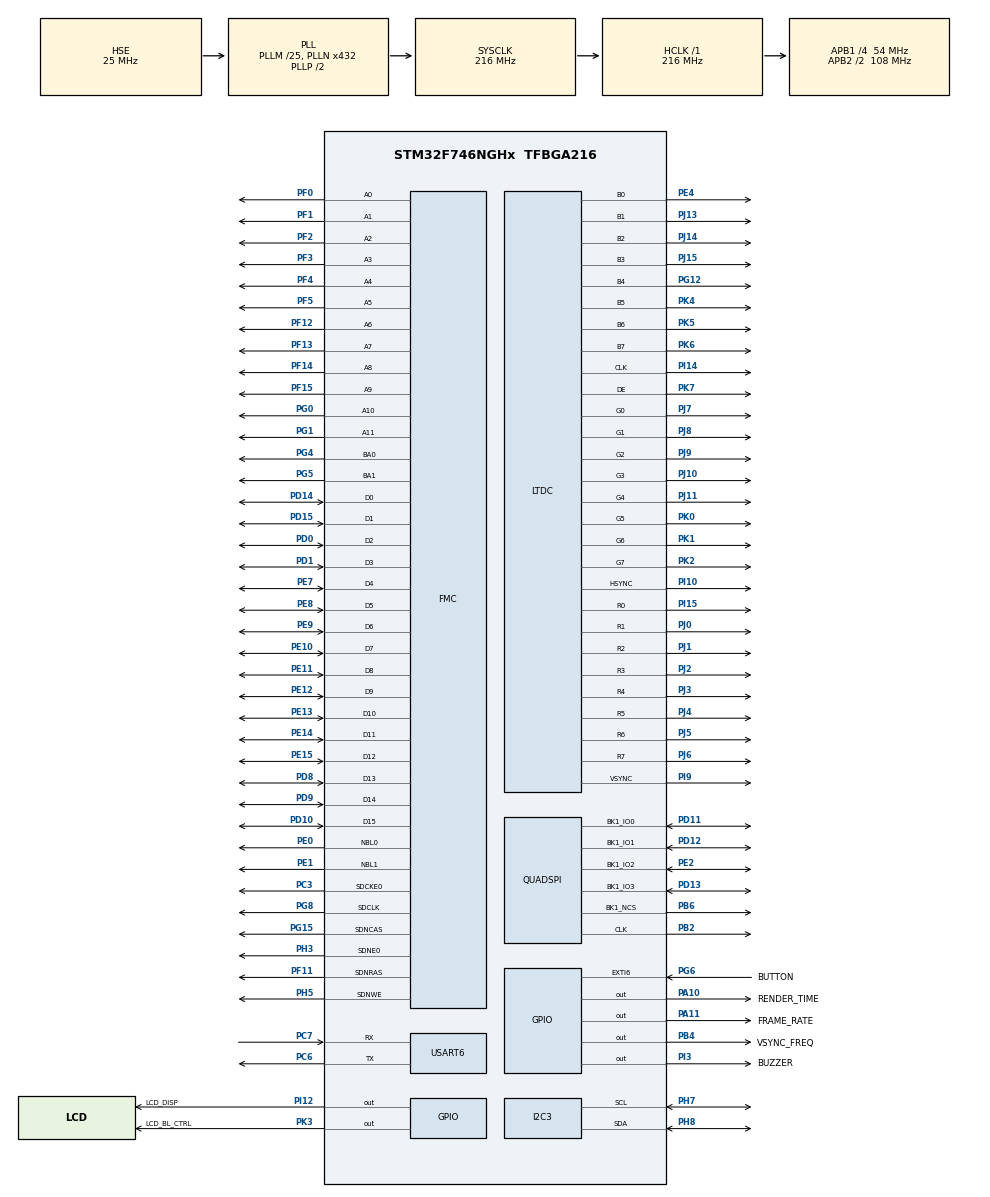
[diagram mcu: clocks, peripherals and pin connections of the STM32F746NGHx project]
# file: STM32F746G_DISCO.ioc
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CORTEX_M7.ART_ACCLERATOR_ENABLE=1
CORTEX_M7.AccessPermission-Cortex_Memory_Protection_Unit_Region0_Settings=MPU_REGION_FULL_ACCESS
CORTEX_M7.AccessPermission-Cortex_Memory_Protection_Unit_Region1_Settings=MPU_REGION_FULL_ACCESS
CORTEX_M7.BaseAddress-Cortex_Memory_Protection_Unit_Region0_Settings=0x90000000
CORTEX_M7.BaseAddress-Cortex_Memory_Protection_Unit_Region1_Settings=0x90000000
CORTEX_M7.CPU_DCache=Enabled
CORTEX_M7.CPU_ICache=Enabled
CORTEX_M7.Enable-Cortex_Memory_Protection_Unit_Region0_Settings=MPU_REGION_ENABLE
CORTEX_M7.Enable-Cortex_Memory_Protection_Unit_Region1_Settings=MPU_REGION_ENABLE
CORTEX_M7.IsCacheable-Cortex_Memory_Protection_Unit_Region1_Settings=MPU_ACCESS_CACHEABLE
CORTEX_M7.MPU_Control=MPU_PRIVILEGED_DEFAULT
CORTEX_M7.PREFETCH_ENABLE=1
CORTEX_M7.Size-Cortex_Memory_Protection_Unit_Region0_Settings=MPU_REGION_SIZE_256MB
CORTEX_M7.Size-Cortex_Memory_Protection_Unit_Region1_Settings=MPU_REGION_SIZE_16MB
FMC.CASLatency1=FMC_SDRAM_CAS_LATENCY_3
FMC.ExitSelfRefreshDelay1=7
FMC.LoadToActiveDelay1=2
FMC.RCDDelay1=2
FMC.RPDelay1=2
FMC.ReadBurst1=FMC_SDRAM_RBURST_ENABLE
FMC.RowCycleDelay1=7
FMC.SDClockPeriod1=FMC_SDRAM_CLOCK_PERIOD_2
FMC.SelfRefreshTime1=4
FMC.WriteRecoveryTime1=3
FREERTOS.Queues01=uartQueue,2,uint8_t,0,Dynamic,NULL,NULL
FREERTOS.Tasks01=defaultTask,24,128,StartDefaultTask,Default,NULL,Dynamic,NULL,NULL;TouchGFXTask,24,4096,TouchGFX_Task,As external,NULL,Dynamic,NULL,NULL;videoTask,8,1000,videoTaskFunc,As external,NULL,Dynamic,NULL,NULL
FREERTOS.configTOTAL_HEAP_SIZE=75000
FREERTOS.configUSE_APPLICATION_TASK_TAG=1
FREERTOS.configUSE_IDLE_HOOK=1
I2C3.Timing=0x20404768
LIBJPEG.RGB_ORDERING=BGR
LTDC.ActiveH=272
LTDC.ActiveW=480
LTDC.Alpha_L0=255
LTDC.FBStartAdress_L0=0xC0000000
LTDC.HBP=13
LTDC.HFP=32
LTDC.HSync=41
LTDC.ImageHeight_L0=272
LTDC.ImageWidth_L0=480
LTDC.Layers=0
LTDC.PixelFormat_L0=LTDC_PIXEL_FORMAT_RGB565
LTDC.VSync=10
LTDC.WindowX1_L0=480
LTDC.WindowY1_L0=272
Mcu.Family=STM32F7
Mcu.Name=STM32F746NGHx
Mcu.Package=TFBGA216
NVIC.DMA2D_IRQn=true\:5\:0\:true\:false\:true\:true\:true\:true\:true
NVIC.EXTI9_5_IRQn=true\:5\:0\:false\:false\:true\:true\:true\:true\:true
NVIC.LTDC_IRQn=true\:5\:0\:true\:false\:true\:true\:true\:true\:true
NVIC.PriorityGroup=NVIC_PRIORITYGROUP_4
NVIC.TIM6_DAC_IRQn=true\:0\:0\:false\:false\:true\:false\:false\:true\:true
NVIC.TimeBase=TIM6_DAC_IRQn
NVIC.TimeBaseIP=TIM6
NVIC.USART6_IRQn=true\:5\:0\:false\:false\:true\:true\:true\:true\:true
PA10.GPIO_Label=RENDER_TIME
PA10.GPIO_Speed=GPIO_SPEED_FREQ_VERY_HIGH
PA10.Signal=GPIO_Output
PA11.GPIO_Label=FRAME_RATE
PA11.GPIO_Speed=GPIO_SPEED_FREQ_VERY_HIGH
PA11.Signal=GPIO_Output
PA13.Mode=Serial_Wire
PA13.Signal=SYS_JTMS-SWDIO
PA14.Mode=Serial_Wire
PA14.Signal=SYS_JTCK-SWCLK
PB2.Mode=Single Bank 1
PB2.Signal=QUADSPI_CLK
PB4.GPIO_Label=VSYNC_FREQ
PB4.GPIO_Speed=GPIO_SPEED_FREQ_VERY_HIGH
PB4.Signal=GPIO_Output
PB6.Mode=Single Bank 1
PB6.Signal=QUADSPI_BK1_NCS
PC3.Mode=SdramChipSelect1_1
PC3.Signal=FMC_SDCKE0
PC6.Mode=Asynchronous
PC6.Signal=USART6_TX
PC7.Mode=Asynchronous
PC7.Signal=USART6_RX
PD0.Signal=FMC_D2_DA2
PD1.Signal=FMC_D3_DA3
PD10.Signal=FMC_D15_DA15
PD11.Mode=Single Bank 1
PD11.Signal=QUADSPI_BK1_IO0
PD12.Mode=Single Bank 1
PD12.Signal=QUADSPI_BK1_IO1
PD13.Mode=Single Bank 1
PD13.Signal=QUADSPI_BK1_IO3
PD14.Signal=FMC_D0_DA0
PD15.Signal=FMC_D1_DA1
PD8.Signal=FMC_D13_DA13
PD9.Signal=FMC_D14_DA14
PE0.Signal=FMC_NBL0
PE1.Signal=FMC_NBL1
PE10.Signal=FMC_D7_DA7
PE11.Signal=FMC_D8_DA8
PE12.Signal=FMC_D9_DA9
PE13.Signal=FMC_D10_DA10
PE14.Signal=FMC_D11_DA11
PE15.Signal=FMC_D12_DA12
PE2.Mode=Single Bank 1
PE2.Signal=QUADSPI_BK1_IO2
PE4.Mode=RGB888
PE4.Signal=LTDC_B0
PE7.Signal=FMC_D4_DA4
PE8.Signal=FMC_D5_DA5
PE9.Signal=FMC_D6_DA6
PF0.Signal=FMC_A0
PF1.Signal=FMC_A1
PF11.Signal=FMC_SDNRAS
PF12.Signal=FMC_A6
PF13.Signal=FMC_A7
PF14.Signal=FMC_A8
PF15.Signal=FMC_A9
PF2.Signal=FMC_A2
PF3.Signal=FMC_A3
PF4.Signal=FMC_A4
PF5.Signal=FMC_A5
PG0.Signal=FMC_A10
PG1.Signal=FMC_A11
PG12.Mode=RGB888
PG12.Signal=LTDC_B4
PG15.Signal=FMC_SDNCAS
PG4.Signal=FMC_A14_BA0
PG5.Signal=FMC_A15_BA1
PG6.GPIO_Label=BUTTON
PG6.GPIO_ModeDefaultEXTI=GPIO_MODE_IT_FALLING
PG6.GPIO_PuPd=GPIO_PULLUP
PG6.Signal=GPXTI6
PG8.Signal=FMC_SDCLK
PH0/OSC_IN.Mode=HSE-External-Oscillator
PH0/OSC_IN.Signal=RCC_OSC_IN
PH1/OSC_OUT.Mode=HSE-External-Oscillator
PH1/OSC_OUT.Signal=RCC_OSC_OUT
PH3.Mode=SdramChipSelect1_1
PH3.Signal=FMC_SDNE0
PH5.Signal=FMC_SDNWE
PH7.GPIO_Pu=GPIO_PULLUP
PH7.Mode=I2C
PH7.Signal=I2C3_SCL
PH8.GPIO_Pu=GPIO_PULLUP
PH8.Mode=I2C
PH8.Signal=I2C3_SDA
PI10.Mode=RGB888
PI10.Signal=LTDC_HSYNC
PI12.GPIO_Label=LCD_DISP
PI12.PinState=GPIO_PIN_SET
PI12.Signal=GPIO_Output
PI14.Mode=RGB888
PI14.Signal=LTDC_CLK
PI15.Mode=RGB888
PI15.Signal=LTDC_R0
PI3.GPIO_Label=BUZZER
PI3.Signal=GPIO_Output
PI9.Mode=RGB888
PI9.Signal=LTDC_VSYNC
PJ0.Mode=RGB888
PJ0.Signal=LTDC_R1
PJ1.Mode=RGB888
PJ1.Signal=LTDC_R2
PJ10.Mode=RGB888
PJ10.Signal=LTDC_G3
PJ11.Mode=RGB888
PJ11.Signal=LTDC_G4
PJ13.Mode=RGB888
PJ13.Signal=LTDC_B1
PJ14.Mode=RGB888
PJ14.Signal=LTDC_B2
PJ15.Mode=RGB888
PJ15.Signal=LTDC_B3
PJ2.Mode=RGB888
PJ2.Signal=LTDC_R3
PJ3.Mode=RGB888
PJ3.Signal=LTDC_R4
PJ4.Mode=RGB888
PJ4.Signal=LTDC_R5
PJ5.Mode=RGB888
PJ5.Signal=LTDC_R6
PJ6.Mode=RGB888
PJ6.Signal=LTDC_R7
PJ7.Mode=RGB888
PJ7.Signal=LTDC_G0
PJ8.Mode=RGB888
PJ8.Signal=LTDC_G1
PJ9.Mode=RGB888
PJ9.Signal=LTDC_G2
PK0.Mode=RGB888
PK0.Signal=LTDC_G5
PK1.Mode=RGB888
PK1.Signal=LTDC_G6
PK2.Mode=RGB888
PK2.Signal=LTDC_G7
PK3.GPIO_Label=LCD_BL_CTRL
PK3.PinState=GPIO_PIN_SET
PK3.Signal=GPIO_Output
PK4.Mode=RGB888
PK4.Signal=LTDC_B5
PK5.Mode=RGB888
PK5.Signal=LTDC_B6
PK6.Mode=RGB888
PK6.Signal=LTDC_B7
PK7.Mode=RGB888
PK7.Signal=LTDC_DE
ProjectManager.HeapSize=0xA00
ProjectManager.StackSize=0xA00
ProjectManager.TargetToolchain=STM32CubeIDE
QUADSPI.ChipSelectHighTime=QSPI_CS_HIGH_TIME_6_CYCLE
QUADSPI.ClockPrescaler=1
QUADSPI.FifoThreshold=4
QUADSPI.FlashSize=24
QUADSPI.SampleShifting=QSPI_SAMPLE_SHIFTING_HALFCYCLE
RCC.AHBFreq_Value=216000000
RCC.APB1CLKDivider=RCC_HCLK_DIV4
RCC.APB1Freq_Value=54000000
RCC.APB1TimFreq_Value=108000000
RCC.APB2CLKDivider=RCC_HCLK_DIV2
RCC.APB2Freq_Value=108000000
RCC.APB2TimFreq_Value=216000000
RCC.CortexFreq_Value=216000000
RCC.HCLKFreq_Value=216000000
RCC.HSE_VALUE=25000000
RCC.HSI_VALUE=16000000
RCC.LSE_VALUE=32768
RCC.PLLI2SN=100
RCC.PLLM=25
RCC.PLLN=432
RCC.PLLSAIN=384
RCC.PLLSAIR=5
RCC.PLLSAIRDiv=RCC_PLLSAIDIVR_8
RCC.PLLSourceVirtual=RCC_PLLSOURCE_HSE
RCC.SYSCLKFreq_VALUE=216000000
RCC.SYSCLKSource=RCC_SYSCLKSOURCE_PLLCLK
RCC.USBFreq_Value=216000000
RCC.VCOOutputFreq_Value=432000000
SH.FMC_A0.0=FMC_A0,12b-sda1
SH.FMC_A1.0=FMC_A1,12b-sda1
SH.FMC_A10.0=FMC_A10,12b-sda1
SH.FMC_A11.0=FMC_A11,12b-sda1
SH.FMC_A14_BA0.0=FMC_BA0,FourSdramBanks1
SH.FMC_A15_BA1.0=FMC_BA1,FourSdramBanks1
SH.FMC_A2.0=FMC_A2,12b-sda1
SH.FMC_A3.0=FMC_A3,12b-sda1
SH.FMC_A4.0=FMC_A4,12b-sda1
SH.FMC_A5.0=FMC_A5,12b-sda1
SH.FMC_A6.0=FMC_A6,12b-sda1
SH.FMC_A7.0=FMC_A7,12b-sda1
SH.FMC_A8.0=FMC_A8,12b-sda1
SH.FMC_A9.0=FMC_A9,12b-sda1
SH.FMC_D0_DA0.0=FMC_D0,sd-16b-d1
SH.FMC_D10_DA10.0=FMC_D10,sd-16b-d1
SH.FMC_D11_DA11.0=FMC_D11,sd-16b-d1
SH.FMC_D12_DA12.0=FMC_D12,sd-16b-d1
SH.FMC_D13_DA13.0=FMC_D13,sd-16b-d1
SH.FMC_D14_DA14.0=FMC_D14,sd-16b-d1
SH.FMC_D15_DA15.0=FMC_D15,sd-16b-d1
SH.FMC_D1_DA1.0=FMC_D1,sd-16b-d1
SH.FMC_D2_DA2.0=FMC_D2,sd-16b-d1
SH.FMC_D3_DA3.0=FMC_D3,sd-16b-d1
SH.FMC_D4_DA4.0=FMC_D4,sd-16b-d1
SH.FMC_D5_DA5.0=FMC_D5,sd-16b-d1
SH.FMC_D6_DA6.0=FMC_D6,sd-16b-d1
SH.FMC_D7_DA7.0=FMC_D7,sd-16b-d1
SH.FMC_D8_DA8.0=FMC_D8,sd-16b-d1
SH.FMC_D9_DA9.0=FMC_D9,sd-16b-d1
SH.FMC_NBL0.0=FMC_NBL0,Sd2ByteEnable1
SH.FMC_NBL1.0=FMC_NBL1,Sd2ByteEnable1
SH.FMC_SDCLK.0=FMC_SDCLK,12b-sda1
SH.FMC_SDNCAS.0=FMC_SDNCAS,12b-sda1
SH.FMC_SDNRAS.0=FMC_SDNRAS,12b-sda1
SH.FMC_SDNWE.0=FMC_SDNWE,12b-sda1
STMicroelectronics.X-CUBE-TOUCHGFX.4.22.1.ApplicationCcGraphicsJjApplication=TouchGFXOoGenerator
STMicroelectronics.X-CUBE-TOUCHGFX.4.22.1.tgfx_address1=0xC0000000
STMicroelectronics.X-CUBE-TOUCHGFX.4.22.1.tgfx_address2=0xC003FC00
STMicroelectronics.X-CUBE-TOUCHGFX.4.22.1.tgfx_buffering_strategy=Double
STMicroelectronics.X-CUBE-TOUCHGFX.4.22.1.tgfx_display_interface=disp_ltdc
STMicroelectronics.X-CUBE-TOUCHGFX.4.22.1.tgfx_hardware_accelerator=dma_2d
STMicroelectronics.X-CUBE-TOUCHGFX.4.22.1.tgfx_location=Allocate
STMicroelectronics.X-CUBE-TOUCHGFX.4.22.1.tgfx_vector_rendering=Enabled
STMicroelectronics.X-CUBE-TOUCHGFX.4.22.1.tgfx_video=Software
STMicroelectronics.X-CUBE-TOUCHGFX.4.22.1.tgfx_video_buffer_format=RGB565\:2
STMicroelectronics.X-CUBE-TOUCHGFX.4.22.1.tgfx_video_height=272
STMicroelectronics.X-CUBE-TOUCHGFX.4.22.1.tgfx_video_strategy=2
STMicroelectronics.X-CUBE-TOUCHGFX.4.22.1.tgfx_video_width=480
STMicroelectronics.X-CUBE-TOUCHGFX.4.22.1.tgfx_vsync=vsync_ltdc
USART6.VirtualMode-Asynchronous=VM_ASYNC
VP_CRC_VS_CRC.Mode=CRC_Activate
VP_DMA2D_VS_DMA2D.Mode=DMA2D_Activate
VP_FREERTOS_VS_CMSIS_V2.Mode=CMSIS_V2
VP_LIBJPEG_VS_JPEGLIB.Mode=Enabled
VP_STMicroelectronics.X-CUBE-TOUCHGFX_VS_GraphicsJjApplication_4.22.1.Mode=GraphicsJjApplication
VP_SYS_VS_tim6.Mode=TIM6
board=custom

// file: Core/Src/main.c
/* USER CODE BEGIN Header */
/**
  ******************************************************************************
  * @file           : main.c
  * @brief          : Main program body
  ******************************************************************************
  * @attention
  *
  * <h2><center>&copy; Copyright (c) 2020 STMicroelectronics.
  * All rights reserved.</center></h2>
  *
  * This software component is licensed by ST under Ultimate Liberty license
  * SLA0044, the "License"; You may not use this file except in compliance with
  * the License. You may obtain a copy of the License at:
  *                             www.st.com/SLA0044
  *
  ******************************************************************************
  */
/* USER CODE END Header */
#include "main.h"
#include "cmsis_os.h"
#include "libjpeg.h"
#include "app_touchgfx.h"

/* USER CODE BEGIN Includes */
#include <stm32746g_discovery_qspi.h>
#include "string.h"
#include <stdbool.h>
/* USER CODE END Includes */

/* USER CODE BEGIN PD */

#define REFRESH_COUNT        1835

#define SDRAM_TIMEOUT                            ((uint32_t)0xFFFF)
#define SDRAM_MODEREG_BURST_LENGTH_1             ((uint16_t)0x0000)
#define SDRAM_MODEREG_BURST_LENGTH_2             ((uint16_t)0x0001)
#define SDRAM_MODEREG_BURST_LENGTH_4             ((uint16_t)0x0002)
#define SDRAM_MODEREG_BURST_LENGTH_8             ((uint16_t)0x0004)
#define SDRAM_MODEREG_BURST_TYPE_SEQUENTIAL      ((uint16_t)0x0000)
#define SDRAM_MODEREG_BURST_TYPE_INTERLEAVED     ((uint16_t)0x0008)
#define SDRAM_MODEREG_CAS_LATENCY_2              ((uint16_t)0x0020)
#define SDRAM_MODEREG_CAS_LATENCY_3              ((uint16_t)0x0030)
#define SDRAM_MODEREG_OPERATING_MODE_STANDARD    ((uint16_t)0x0000)
#define SDRAM_MODEREG_WRITEBURST_MODE_PROGRAMMED ((uint16_t)0x0000)
#define SDRAM_MODEREG_WRITEBURST_MODE_SINGLE     ((uint16_t)0x0200)

/* USER CODE END PD */

CRC_HandleTypeDef hcrc;

DMA2D_HandleTypeDef hdma2d;

I2C_HandleTypeDef hi2c3;

LTDC_HandleTypeDef hltdc;

QSPI_HandleTypeDef hqspi;

UART_HandleTypeDef huart6;

SDRAM_HandleTypeDef hsdram1;

/* Definitions for defaultTask */
osThreadId_t defaultTaskHandle;
const osThreadAttr_t defaultTask_attributes = {
  .name = "defaultTask",
  .stack_size = 128 * 4,
  .priority = (osPriority_t) osPriorityNormal,
};
/* Definitions for TouchGFXTask */
osThreadId_t TouchGFXTaskHandle;
const osThreadAttr_t TouchGFXTask_attributes = {
  .name = "TouchGFXTask",
  .stack_size = 4096 * 4,
  .priority = (osPriority_t) osPriorityNormal,
};
/* Definitions for videoTask */
osThreadId_t videoTaskHandle;
const osThreadAttr_t videoTask_attributes = {
  .name = "videoTask",
  .stack_size = 1000 * 4,
  .priority = (osPriority_t) osPriorityLow,
};
/* Definitions for uartQueue */
osMessageQueueId_t uartQueueHandle;
const osMessageQueueAttr_t uartQueue_attributes = {
  .name = "uartQueue"
};
/* USER CODE BEGIN PV */
static FMC_SDRAM_CommandTypeDef Command;
/* USER CODE END PV */

void SystemClock_Config(void);
static void MPU_Initialize(void);
static void MPU_Config(void);
static void MX_GPIO_Init(void);
static void MX_CRC_Init(void);
static void MX_DMA2D_Init(void);
static void MX_FMC_Init(void);
static void MX_I2C3_Init(void);
static void MX_LTDC_Init(void);
static void MX_QUADSPI_Init(void);
static void MX_USART6_UART_Init(void);
void StartDefaultTask(void *argument);
extern void TouchGFX_Task(void *argument);
extern void videoTaskFunc(void *argument);

/* USER CODE BEGIN PFP */

extern void toggleBuzzer(void)
{
	HAL_GPIO_TogglePin(GPIOI, GPIO_PIN_3);
}

extern void toggleBuzzerOff(void)
{
	HAL_GPIO_WritePin(GPIOI, GPIO_PIN_3, GPIO_PIN_RESET);
}

/* USER CODE END PFP */

/* USER CODE BEGIN 0 */

uint8_t RxData[257];
uartData_t *uartData_q;
volatile bool button = false;

void HAL_UARTEx_RxEventCallback(UART_HandleTypeDef *huart, uint16_t Size)
{
	RxData[Size] = '\0';
	if(osMessageQueueGetSpace(uartQueueHandle) > 0)
	{
		strncpy(uartData_q->Data, (char *)RxData, Size + 1);
		uartData_q->size = Size + 1;
		osMessageQueuePut(uartQueueHandle, &uartData_q, 0, 0);

	}

	HAL_UARTEx_ReceiveToIdle_IT(&huart6, RxData, 256);
}

/* USER CODE END 0 */

int main(void)
{

  /* Enable I-Cache---------------------------------------------------------*/
  SCB_EnableICache();

  /* Enable D-Cache---------------------------------------------------------*/
  SCB_EnableDCache();

  /* MCU Configuration--------------------------------------------------------*/

  /* Reset of all peripherals, Initializes the Flash interface and the Systick. */
  HAL_Init();

  /* MPU Configuration--------------------------------------------------------*/
  MPU_Config();

  /* Configure the system clock */
  SystemClock_Config();

  /* Initialize all configured peripherals */
  MX_GPIO_Init();
  MX_CRC_Init();
  MX_DMA2D_Init();
  MX_FMC_Init();
  MX_I2C3_Init();
  MX_LTDC_Init();
  MX_QUADSPI_Init();
  MX_LIBJPEG_Init();
  MX_USART6_UART_Init();
  MX_TouchGFX_Init();
  /* Call PreOsInit function */
  MX_TouchGFX_PreOSInit();

  /* Init scheduler */
  osKernelInitialize();

  /* Create the queue(s) */
  /* creation of uartQueue */
  uartQueueHandle = osMessageQueueNew (2, sizeof(uint8_t), &uartQueue_attributes);

  /* Create the thread(s) */
  /* creation of defaultTask */
  defaultTaskHandle = osThreadNew(StartDefaultTask, NULL, &defaultTask_attributes);

  /* creation of TouchGFXTask */
  TouchGFXTaskHandle = osThreadNew(TouchGFX_Task, NULL, &TouchGFXTask_attributes);

  /* creation of videoTask */
  videoTaskHandle = osThreadNew(videoTaskFunc, NULL, &videoTask_attributes);

  /* Start scheduler */
  osKernelStart();

  /* We should never get here as control is now taken by the scheduler */
  /* Infinite loop */
  while (1)
  {

  }
}

void SystemClock_Config(void)
{
  RCC_OscInitTypeDef RCC_OscInitStruct = {0};
  RCC_ClkInitTypeDef RCC_ClkInitStruct = {0};

  /** Configure the main internal regulator output voltage
  */
  __HAL_RCC_PWR_CLK_ENABLE();
  __HAL_PWR_VOLTAGESCALING_CONFIG(PWR_REGULATOR_VOLTAGE_SCALE1);

  /** Initializes the RCC Oscillators according to the specified parameters
  * in the RCC_OscInitTypeDef structure.
  */
  RCC_OscInitStruct.OscillatorType = RCC_OSCILLATORTYPE_HSE;
  RCC_OscInitStruct.HSEState = RCC_HSE_ON;
  RCC_OscInitStruct.PLL.PLLState = RCC_PLL_ON;
  RCC_OscInitStruct.PLL.PLLSource = RCC_PLLSOURCE_HSE;
  RCC_OscInitStruct.PLL.PLLM = 25;
  RCC_OscInitStruct.PLL.PLLN = 432;
  RCC_OscInitStruct.PLL.PLLP = RCC_PLLP_DIV2;
  RCC_OscInitStruct.PLL.PLLQ = 2;
  if (HAL_RCC_OscConfig(&RCC_OscInitStruct) != HAL_OK)
  {
    Error_Handler();
  }

  /** Activate the Over-Drive mode
  */
  if (HAL_PWREx_EnableOverDrive() != HAL_OK)
  {
    Error_Handler();
  }

  /** Initializes the CPU, AHB and APB buses clocks
  */
  RCC_ClkInitStruct.ClockType = RCC_CLOCKTYPE_HCLK|RCC_CLOCKTYPE_SYSCLK
                              |RCC_CLOCKTYPE_PCLK1|RCC_CLOCKTYPE_PCLK2;
  RCC_ClkInitStruct.SYSCLKSource = RCC_SYSCLKSOURCE_PLLCLK;
  RCC_ClkInitStruct.AHBCLKDivider = RCC_SYSCLK_DIV1;
  RCC_ClkInitStruct.APB1CLKDivider = RCC_HCLK_DIV4;
  RCC_ClkInitStruct.APB2CLKDivider = RCC_HCLK_DIV2;

  if (HAL_RCC_ClockConfig(&RCC_ClkInitStruct, FLASH_LATENCY_7) != HAL_OK)
  {
    Error_Handler();
  }
}

static void MX_CRC_Init(void)
{

  hcrc.Instance = CRC;
  hcrc.Init.DefaultPolynomialUse = DEFAULT_POLYNOMIAL_ENABLE;
  hcrc.Init.DefaultInitValueUse = DEFAULT_INIT_VALUE_ENABLE;
  hcrc.Init.InputDataInversionMode = CRC_INPUTDATA_INVERSION_NONE;
  hcrc.Init.OutputDataInversionMode = CRC_OUTPUTDATA_INVERSION_DISABLE;
  hcrc.InputDataFormat = CRC_INPUTDATA_FORMAT_BYTES;
  if (HAL_CRC_Init(&hcrc) != HAL_OK)
  {
    Error_Handler();
  }

}

static void MX_DMA2D_Init(void)
{

  hdma2d.Instance = DMA2D;
  hdma2d.Init.Mode = DMA2D_M2M;
  hdma2d.Init.ColorMode = DMA2D_OUTPUT_ARGB8888;
  hdma2d.Init.OutputOffset = 0;
  hdma2d.LayerCfg[1].InputOffset = 0;
  hdma2d.LayerCfg[1].InputColorMode = DMA2D_INPUT_ARGB8888;
  hdma2d.LayerCfg[1].AlphaMode = DMA2D_NO_MODIF_ALPHA;
  hdma2d.LayerCfg[1].InputAlpha = 0;
  if (HAL_DMA2D_Init(&hdma2d) != HAL_OK)
  {
    Error_Handler();
  }
  if (HAL_DMA2D_ConfigLayer(&hdma2d, 1) != HAL_OK)
  {
    Error_Handler();
  }

}

static void MX_I2C3_Init(void)
{

  /* USER CODE BEGIN I2C3_Init 0 */
  HAL_Delay(100); //Delay to fix initialization issue on some boards
  /* USER CODE END I2C3_Init 0 */

  hi2c3.Instance = I2C3;
  hi2c3.Init.Timing = 0x20404768;
  hi2c3.Init.OwnAddress1 = 0;
  hi2c3.Init.AddressingMode = I2C_ADDRESSINGMODE_7BIT;
  hi2c3.Init.DualAddressMode = I2C_DUALADDRESS_DISABLE;
  hi2c3.Init.OwnAddress2 = 0;
  hi2c3.Init.OwnAddress2Masks = I2C_OA2_NOMASK;
  hi2c3.Init.GeneralCallMode = I2C_GENERALCALL_DISABLE;
  hi2c3.Init.NoStretchMode = I2C_NOSTRETCH_DISABLE;
  if (HAL_I2C_Init(&hi2c3) != HAL_OK)
  {
    Error_Handler();
  }

  /** Configure Analogue filter
  */
  if (HAL_I2CEx_ConfigAnalogFilter(&hi2c3, I2C_ANALOGFILTER_ENABLE) != HAL_OK)
  {
    Error_Handler();
  }

  /** Configure Digital filter
  */
  if (HAL_I2CEx_ConfigDigitalFilter(&hi2c3, 0) != HAL_OK)
  {
    Error_Handler();
  }

}

static void MX_LTDC_Init(void)
{

  LTDC_LayerCfgTypeDef pLayerCfg = {0};

  hltdc.Instance = LTDC;
  hltdc.Init.HSPolarity = LTDC_HSPOLARITY_AL;
  hltdc.Init.VSPolarity = LTDC_VSPOLARITY_AL;
  hltdc.Init.DEPolarity = LTDC_DEPOLARITY_AL;
  hltdc.Init.PCPolarity = LTDC_PCPOLARITY_IPC;
  hltdc.Init.HorizontalSync = 40;
  hltdc.Init.VerticalSync = 9;
  hltdc.Init.AccumulatedHBP = 53;
  hltdc.Init.AccumulatedVBP = 11;
  hltdc.Init.AccumulatedActiveW = 533;
  hltdc.Init.AccumulatedActiveH = 283;
  hltdc.Init.TotalWidth = 565;
  hltdc.Init.TotalHeigh = 285;
  hltdc.Init.Backcolor.Blue = 0;
  hltdc.Init.Backcolor.Green = 0;
  hltdc.Init.Backcolor.Red = 0;
  if (HAL_LTDC_Init(&hltdc) != HAL_OK)
  {
    Error_Handler();
  }
  pLayerCfg.WindowX0 = 0;
  pLayerCfg.WindowX1 = 480;
  pLayerCfg.WindowY0 = 0;
  pLayerCfg.WindowY1 = 272;
  pLayerCfg.PixelFormat = LTDC_PIXEL_FORMAT_RGB565;
  pLayerCfg.Alpha = 255;
  pLayerCfg.Alpha0 = 0;
  pLayerCfg.BlendingFactor1 = LTDC_BLENDING_FACTOR1_CA;
  pLayerCfg.BlendingFactor2 = LTDC_BLENDING_FACTOR2_CA;
  pLayerCfg.FBStartAdress = 0xC0000000;
  pLayerCfg.ImageWidth = 480;
  pLayerCfg.ImageHeight = 272;
  pLayerCfg.Backcolor.Blue = 0;
  pLayerCfg.Backcolor.Green = 0;
  pLayerCfg.Backcolor.Red = 0;
  if (HAL_LTDC_ConfigLayer(&hltdc, &pLayerCfg, 0) != HAL_OK)
  {
    Error_Handler();
  }

}

static void MX_QUADSPI_Init(void)
{

  /* QUADSPI parameter configuration*/
  hqspi.Instance = QUADSPI;
  hqspi.Init.ClockPrescaler = 1;
  hqspi.Init.FifoThreshold = 4;
  hqspi.Init.SampleShifting = QSPI_SAMPLE_SHIFTING_HALFCYCLE;
  hqspi.Init.FlashSize = 24;
  hqspi.Init.ChipSelectHighTime = QSPI_CS_HIGH_TIME_6_CYCLE;
  hqspi.Init.ClockMode = QSPI_CLOCK_MODE_0;
  hqspi.Init.FlashID = QSPI_FLASH_ID_1;
  hqspi.Init.DualFlash = QSPI_DUALFLASH_DISABLE;
  if (HAL_QSPI_Init(&hqspi) != HAL_OK)
  {
    Error_Handler();
  }
  /* USER CODE BEGIN QUADSPI_Init 2 */
  BSP_QSPI_Init();

  BSP_QSPI_MemoryMappedMode();
  HAL_NVIC_DisableIRQ(QUADSPI_IRQn);
  /* USER CODE END QUADSPI_Init 2 */

}

static void MX_USART6_UART_Init(void)
{

  huart6.Instance = USART6;
  huart6.Init.BaudRate = 115200;
  huart6.Init.WordLength = UART_WORDLENGTH_8B;
  huart6.Init.StopBits = UART_STOPBITS_1;
  huart6.Init.Parity = UART_PARITY_NONE;
  huart6.Init.Mode = UART_MODE_TX_RX;
  huart6.Init.HwFlowCtl = UART_HWCONTROL_NONE;
  huart6.Init.OverSampling = UART_OVERSAMPLING_16;
  huart6.Init.OneBitSampling = UART_ONE_BIT_SAMPLE_DISABLE;
  huart6.AdvancedInit.AdvFeatureInit = UART_ADVFEATURE_NO_INIT;
  if (HAL_UART_Init(&huart6) != HAL_OK)
  {
    Error_Handler();
  }

}

/* FMC initialization function */
static void MX_FMC_Init(void)
{

  FMC_SDRAM_TimingTypeDef SdramTiming = {0};

  /** Perform the SDRAM1 memory initialization sequence
  */
  hsdram1.Instance = FMC_SDRAM_DEVICE;
  /* hsdram1.Init */
  hsdram1.Init.SDBank = FMC_SDRAM_BANK1;
  hsdram1.Init.ColumnBitsNumber = FMC_SDRAM_COLUMN_BITS_NUM_8;
  hsdram1.Init.RowBitsNumber = FMC_SDRAM_ROW_BITS_NUM_12;
  hsdram1.Init.MemoryDataWidth = FMC_SDRAM_MEM_BUS_WIDTH_16;
  hsdram1.Init.InternalBankNumber = FMC_SDRAM_INTERN_BANKS_NUM_4;
  hsdram1.Init.CASLatency = FMC_SDRAM_CAS_LATENCY_3;
  hsdram1.Init.WriteProtection = FMC_SDRAM_WRITE_PROTECTION_DISABLE;
  hsdram1.Init.SDClockPeriod = FMC_SDRAM_CLOCK_PERIOD_2;
  hsdram1.Init.ReadBurst = FMC_SDRAM_RBURST_ENABLE;
  hsdram1.Init.ReadPipeDelay = FMC_SDRAM_RPIPE_DELAY_0;
  /* SdramTiming */
  SdramTiming.LoadToActiveDelay = 2;
  SdramTiming.ExitSelfRefreshDelay = 7;
  SdramTiming.SelfRefreshTime = 4;
  SdramTiming.RowCycleDelay = 7;
  SdramTiming.WriteRecoveryTime = 3;
  SdramTiming.RPDelay = 2;
  SdramTiming.RCDDelay = 2;

  if (HAL_SDRAM_Init(&hsdram1, &SdramTiming) != HAL_OK)
  {
    Error_Handler( );
  }

  /* USER CODE BEGIN FMC_Init 2 */
  __IO uint32_t tmpmrd = 0;

    /* Step 1: Configure a clock configuration enable command */
    Command.CommandMode            = FMC_SDRAM_CMD_CLK_ENABLE;
    Command.CommandTarget          =  FMC_SDRAM_CMD_TARGET_BANK1;
    Command.AutoRefreshNumber      = 1;
    Command.ModeRegisterDefinition = 0;

    /* Send the command */
    HAL_SDRAM_SendCommand(&hsdram1, &Command, SDRAM_TIMEOUT);

    /* Step 2: Insert 100 us minimum delay */
    /* Inserted delay is equal to 1 ms due to systick time base unit (ms) */
    HAL_Delay(1);

    /* Step 3: Configure a PALL (precharge all) command */
    Command.CommandMode            = FMC_SDRAM_CMD_PALL;
    Command.CommandTarget          = FMC_SDRAM_CMD_TARGET_BANK1;
    Command.AutoRefreshNumber      = 1;
    Command.ModeRegisterDefinition = 0;

    /* Send the command */
    HAL_SDRAM_SendCommand(&hsdram1, &Command, SDRAM_TIMEOUT);

    /* Step 4: Configure an Auto Refresh command */
    Command.CommandMode            = FMC_SDRAM_CMD_AUTOREFRESH_MODE;
    Command.CommandTarget          = FMC_SDRAM_CMD_TARGET_BANK1;
    Command.AutoRefreshNumber      = 8;
    Command.ModeRegisterDefinition = 0;

    /* Send the command */
    HAL_SDRAM_SendCommand(&hsdram1, &Command, SDRAM_TIMEOUT);

    /* Step 5: Program the external memory mode register */
    tmpmrd = (uint32_t)SDRAM_MODEREG_BURST_LENGTH_1 | \
             SDRAM_MODEREG_BURST_TYPE_SEQUENTIAL    | \
             SDRAM_MODEREG_CAS_LATENCY_3            | \
             SDRAM_MODEREG_OPERATING_MODE_STANDARD  | \
             SDRAM_MODEREG_WRITEBURST_MODE_SINGLE;

    Command.CommandMode            = FMC_SDRAM_CMD_LOAD_MODE;
    Command.CommandTarget          = FMC_SDRAM_CMD_TARGET_BANK1;
    Command.AutoRefreshNumber      = 1;
    Command.ModeRegisterDefinition = tmpmrd;

    /* Send the command */
    HAL_SDRAM_SendCommand(&hsdram1, &Command, SDRAM_TIMEOUT);

    /* Step 6: Set the refresh rate counter */
    /* Set the device refresh rate */
    HAL_SDRAM_ProgramRefreshRate(&hsdram1, REFRESH_COUNT);

    //Deactivate speculative/cache access to first FMC Bank to save FMC bandwidth
    FMC_Bank1->BTCR[0] = 0x000030D2;
  /* USER CODE END FMC_Init 2 */
}

static void MX_GPIO_Init(void)
{
  GPIO_InitTypeDef GPIO_InitStruct = {0};

  /* GPIO Ports Clock Enable */
  __HAL_RCC_GPIOE_CLK_ENABLE();
  __HAL_RCC_GPIOB_CLK_ENABLE();
  __HAL_RCC_GPIOA_CLK_ENABLE();
  __HAL_RCC_GPIOG_CLK_ENABLE();
  __HAL_RCC_GPIOJ_CLK_ENABLE();
  __HAL_RCC_GPIOD_CLK_ENABLE();
  __HAL_RCC_GPIOK_CLK_ENABLE();
  __HAL_RCC_GPIOI_CLK_ENABLE();
  __HAL_RCC_GPIOF_CLK_ENABLE();
  __HAL_RCC_GPIOH_CLK_ENABLE();
  __HAL_RCC_GPIOC_CLK_ENABLE();

  /*Configure GPIO pin Output Level */
  HAL_GPIO_WritePin(VSYNC_FREQ_GPIO_Port, VSYNC_FREQ_Pin, GPIO_PIN_RESET);

  /*Configure GPIO pin Output Level */
  HAL_GPIO_WritePin(BUZZER_GPIO_Port, BUZZER_Pin, GPIO_PIN_RESET);

  /*Configure GPIO pin Output Level */
  HAL_GPIO_WritePin(GPIOA, FRAME_RATE_Pin|RENDER_TIME_Pin, GPIO_PIN_RESET);

  /*Configure GPIO pin Output Level */
  HAL_GPIO_WritePin(LCD_BL_CTRL_GPIO_Port, LCD_BL_CTRL_Pin, GPIO_PIN_SET);

  /*Configure GPIO pin Output Level */
  HAL_GPIO_WritePin(LCD_DISP_GPIO_Port, LCD_DISP_Pin, GPIO_PIN_SET);

  /*Configure GPIO pin : VSYNC_FREQ_Pin */
  GPIO_InitStruct.Pin = VSYNC_FREQ_Pin;
  GPIO_InitStruct.Mode = GPIO_MODE_OUTPUT_PP;
  GPIO_InitStruct.Pull = GPIO_NOPULL;
  GPIO_InitStruct.Speed = GPIO_SPEED_FREQ_VERY_HIGH;
  HAL_GPIO_Init(VSYNC_FREQ_GPIO_Port, &GPIO_InitStruct);

  /*Configure GPIO pins : BUZZER_Pin LCD_DISP_Pin */
  GPIO_InitStruct.Pin = BUZZER_Pin|LCD_DISP_Pin;
  GPIO_InitStruct.Mode = GPIO_MODE_OUTPUT_PP;
  GPIO_InitStruct.Pull = GPIO_NOPULL;
  GPIO_InitStruct.Speed = GPIO_SPEED_FREQ_LOW;
  HAL_GPIO_Init(GPIOI, &GPIO_InitStruct);

  /*Configure GPIO pins : FRAME_RATE_Pin RENDER_TIME_Pin */
  GPIO_InitStruct.Pin = FRAME_RATE_Pin|RENDER_TIME_Pin;
  GPIO_InitStruct.Mode = GPIO_MODE_OUTPUT_PP;
  GPIO_InitStruct.Pull = GPIO_NOPULL;
  GPIO_InitStruct.Speed = GPIO_SPEED_FREQ_VERY_HIGH;
  HAL_GPIO_Init(GPIOA, &GPIO_InitStruct);

  /*Configure GPIO pin : LCD_BL_CTRL_Pin */
  GPIO_InitStruct.Pin = LCD_BL_CTRL_Pin;
  GPIO_InitStruct.Mode = GPIO_MODE_OUTPUT_PP;
  GPIO_InitStruct.Pull = GPIO_NOPULL;
  GPIO_InitStruct.Speed = GPIO_SPEED_FREQ_LOW;
  HAL_GPIO_Init(LCD_BL_CTRL_GPIO_Port, &GPIO_InitStruct);

  /*Configure GPIO pin : BUTTON_Pin */
  GPIO_InitStruct.Pin = BUTTON_Pin;
  GPIO_InitStruct.Mode = GPIO_MODE_IT_FALLING;
  GPIO_InitStruct.Pull = GPIO_PULLUP;
  HAL_GPIO_Init(BUTTON_GPIO_Port, &GPIO_InitStruct);

  /* EXTI interrupt init*/
  HAL_NVIC_SetPriority(EXTI9_5_IRQn, 5, 0);
  HAL_NVIC_EnableIRQ(EXTI9_5_IRQn);

}

/* USER CODE BEGIN 4 */

void HAL_GPIO_EXTI_Callback(uint16_t GPIO_Pin)
{
	if(GPIO_Pin == GPIO_PIN_6)
	{
		button = true;
	}
}

/* USER CODE END 4 */

void StartDefaultTask(void *argument)
{
  /* USER CODE BEGIN 5 */

	HAL_UARTEx_ReceiveToIdle_IT(&huart6, RxData, 256);
  /* Infinite loop */
  for(;;)
  {
    osDelay(100);
  }
  /* USER CODE END 5 */
}

/* MPU Configuration */

void MPU_Config(void)
{
  MPU_Region_InitTypeDef MPU_InitStruct = {0};

  /* Disables the MPU */
  HAL_MPU_Disable();

  /** Initializes and configures the Region and the memory to be protected
  */
  MPU_InitStruct.Enable = MPU_REGION_ENABLE;
  MPU_InitStruct.Number = MPU_REGION_NUMBER0;
  MPU_InitStruct.BaseAddress = 0x90000000;
  MPU_InitStruct.Size = MPU_REGION_SIZE_256MB;
  MPU_InitStruct.SubRegionDisable = 0x0;
  MPU_InitStruct.TypeExtField = MPU_TEX_LEVEL0;
  MPU_InitStruct.AccessPermission = MPU_REGION_FULL_ACCESS;
  MPU_InitStruct.DisableExec = MPU_INSTRUCTION_ACCESS_ENABLE;
  MPU_InitStruct.IsShareable = MPU_ACCESS_NOT_SHAREABLE;
  MPU_InitStruct.IsCacheable = MPU_ACCESS_NOT_CACHEABLE;
  MPU_InitStruct.IsBufferable = MPU_ACCESS_NOT_BUFFERABLE;

  HAL_MPU_ConfigRegion(&MPU_InitStruct);

  /** Initializes and configures the Region and the memory to be protected
  */
  MPU_InitStruct.Number = MPU_REGION_NUMBER1;
  MPU_InitStruct.Size = MPU_REGION_SIZE_16MB;
  MPU_InitStruct.IsCacheable = MPU_ACCESS_CACHEABLE;

  HAL_MPU_ConfigRegion(&MPU_InitStruct);
  /* Enables the MPU */
  HAL_MPU_Enable(MPU_PRIVILEGED_DEFAULT);

}

void HAL_TIM_PeriodElapsedCallback(TIM_HandleTypeDef *htim)
{
  if (htim->Instance == TIM6) {
    HAL_IncTick();
  }
}

void Error_Handler(void)
{
}
